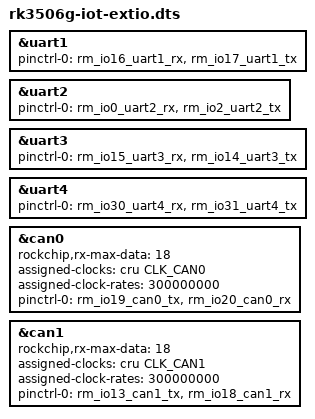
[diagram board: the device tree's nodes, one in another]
/*
 * Copyright (c) 2025 Vanxoak Electronics Co., Ltd.
 */
#include <dt-bindings/clock/rockchip,rk3506-cru.h>
#include <dt-bindings/gpio/gpio.h>
#include <dt-bindings/interrupt-controller/irq.h>
#include <dt-bindings/pinctrl/rockchip.h>"

/dts-v1/;
/plugin/;

&uart1 {
    pinctrl-names = "default";
	pinctrl-0 = <&rm_io16_uart1_rx &rm_io17_uart1_tx>;
	status = "okay";
};
&uart2 {
    pinctrl-names = "default";
	pinctrl-0 = <&rm_io0_uart2_rx &rm_io2_uart2_tx>;
	status = "okay";
};
&uart3 {
    pinctrl-names = "default";
	pinctrl-0 = <&rm_io15_uart3_rx &rm_io14_uart3_tx>;
	status = "okay";
};
&uart4 {
    pinctrl-names = "default";
	pinctrl-0 = <&rm_io30_uart4_rx &rm_io31_uart4_tx>;
	status = "okay";
};
&can0 {
	rockchip,rx-max-data = <18>;
	assigned-clocks = <&cru CLK_CAN0>;
	assigned-clock-rates = <300000000>;
	pinctrl-0 = <&rm_io19_can0_tx &rm_io20_can0_rx>;
	pinctrl-names = "default";
	status = "okay";
};
&can1 {
	rockchip,rx-max-data = <18>;
	assigned-clocks = <&cru CLK_CAN1>;
	assigned-clock-rates = <300000000>;
	pinctrl-0 = <&rm_io13_can1_tx &rm_io18_can1_rx>;
	pinctrl-names = "default";
	status = "okay";
};
